VERSION ""

NS_ :

BS_:

BU_: Device Host

BO_ 3221225472 VECTOR__INDEPENDENT_SIG_MSG: 0 Vector__XXX
 SG_ IsolationDCDCShutdownReq : 0|1@1+ (1,0) [0|1] "" Vector__XXX
 SG_ DCDC_OutputVoltage : 0|9@1+ (0.1,0) [0|51.1] "V" Vector__XXX
 SG_ DCDC_OutputCurrent : 0|14@1- (0.1,0) [-819.2|819.1] "A" Vector__XXX
 SG_ DCDC_InputCurrent : 0|9@1- (0.1,0) [-25.6|25.5] "A" Vector__XXX
 SG_ DCDC_InputVoltage : 0|13@1+ (0.1,0) [0|819.1] "V" Vector__XXX

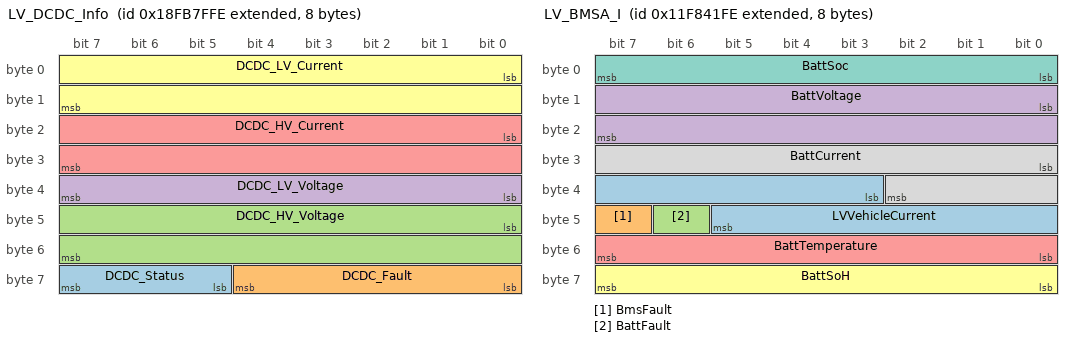
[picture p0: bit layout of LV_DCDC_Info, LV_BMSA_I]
BO_ 2566619134 LV_DCDC_Info: 8 Vector__XXX
 SG_ DCDC_Status : 61|3@1+ (1,0) [0|7] "" Vector__XXX
 SG_ DCDC_Fault : 56|5@1+ (1,0) [0|31] "" Vector__XXX
 SG_ DCDC_HV_Voltage : 40|16@1+ (0.1,0) [0|6553.5] "V" Vector__XXX
 SG_ DCDC_LV_Voltage : 32|8@1+ (0.2,0) [0|51] "V" Vector__XXX
 SG_ DCDC_HV_Current : 16|16@1+ (0.05,-1600) [-1600|1676.75] "A" Vector__XXX
 SG_ DCDC_LV_Current : 0|16@1+ (0.05,-1600) [-1600|1676.75] "A" Vector__XXX

BO_ 2448966142 LV_BMSA_I: 8 Vector__XXX
 SG_ LVVehicleCurrent : 35|11@1+ (0.25,-255) [-255|255] "A" Vector__XXX
 SG_ BmsFault : 47|1@1+ (1,0) [0|1] "" Vector__XXX
 SG_ BattFault : 46|1@1+ (1,0) [0|1] "" Vector__XXX
 SG_ BattVoltage : 8|16@1+ (0.001,0) [0|64.255] "V" Vector__XXX
 SG_ BattTemperature : 48|8@1+ (1,-40) [-40|210] "C" Vector__XXX
 SG_ BattSoH : 56|8@1+ (0.5,0) [0|125] "%" Vector__XXX
 SG_ BattSoc : 0|8@1+ (0.5,0) [0|125] "%" Vector__XXX
 SG_ BattCurrent : 24|11@1+ (0.25,-255) [-255|255] "A" Vector__XXX

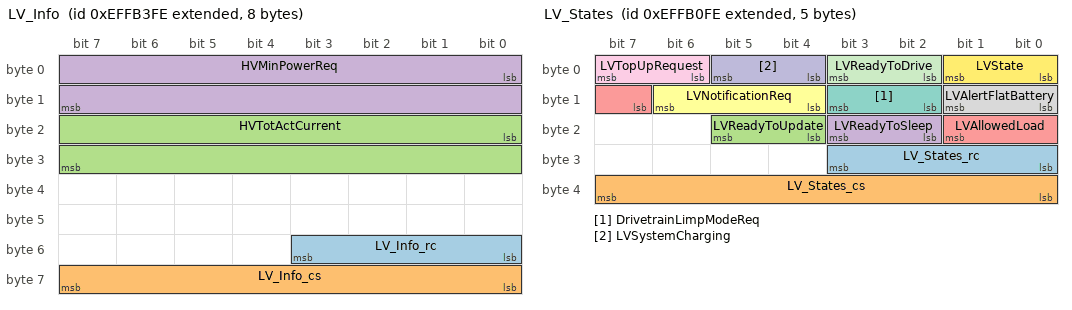
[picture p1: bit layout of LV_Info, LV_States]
BO_ 2399122430 LV_Info: 8 Vector__XXX
 SG_ LV_Info_rc : 48|4@1+ (1,0) [0|15] "" Vector__XXX
 SG_ LV_Info_cs : 56|8@1+ (1,0) [0|255] "" Vector__XXX
 SG_ HVTotActCurrent : 16|16@1+ (0.05,0) [0|3276.75] "A" Vector__XXX
 SG_ HVMinPowerReq : 0|16@1+ (0.1,0) [0|6553.5] "kW" Vector__XXX

BO_ 2399121662 LV_States: 5 Vector__XXX
 SG_ LV_States_rc : 24|4@1+ (1,0) [0|15] "" Vector__XXX
 SG_ LV_States_cs : 32|8@1+ (1,0) [0|255] "" Vector__XXX
 SG_ LVReadyToUpdate : 20|2@1+ (1,0) [0|3] "" Vector__XXX
 SG_ LVReadyToSleep : 18|2@1+ (1,0) [0|3] "" Vector__XXX
 SG_ LVAllowedLoad : 15|3@1+ (1,0) [0|7] "" Vector__XXX
 SG_ LVNotificationReq : 12|3@1+ (1,0) [0|7] "" Vector__XXX
 SG_ DrivetrainLimpModeReq : 10|2@1+ (1,0) [0|3] "" Vector__XXX
 SG_ LVAlertFlatBattery : 8|2@1+ (1,0) [0|3] "" Vector__XXX
 SG_ LVTopUpRequest : 6|2@1+ (1,0) [0|3] "" Vector__XXX
 SG_ LVSystemCharging : 4|2@1+ (1,0) [0|3] "" Vector__XXX
 SG_ LVReadyToDrive : 2|2@1+ (1,0) [0|3] "" Vector__XXX
 SG_ LVState : 0|2@1+ (1,0) [0|3] "" Vector__XXX

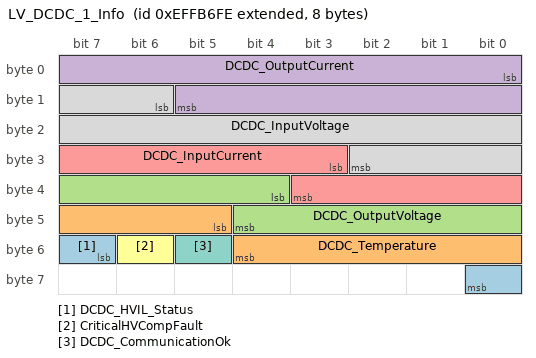
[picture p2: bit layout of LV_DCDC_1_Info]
BO_ 2399123198 LV_DCDC_1_Info: 8 Vector__XXX
 SG_ DCDC_HVIL_Status : 55|2@1+ (1,0) [0|0] "" Vector__XXX
 SG_ DCDC_Temperature : 45|8@1+ (1,-40) [-40|215] "Degree Celsius" Vector__XXX
 SG_ DCDC_OutputVoltage : 36|9@1+ (0.1,0) [0|51.1] "V" Vector__XXX
 SG_ DCDC_OutputCurrent : 0|14@1- (0.1,0) [-819.2|819.1] "A" Vector__XXX
 SG_ DCDC_InputCurrent : 27|9@1- (0.1,0) [-25.6|25.5] "A" Vector__XXX
 SG_ CriticalHVCompFault : 54|1@1+ (1,0) [0|1] "" Vector__XXX
 SG_ DCDC_CommunicationOk : 53|1@1+ (1,0) [0|1] "" Vector__XXX
 SG_ DCDC_InputVoltage : 14|13@1+ (0.1,0) [0|819.1] "V" Vector__XXX

CM_ "$File: //depot/auto/dbc/Software_Modules/LV_System/LVSYSOP/0.2.9.0/LVSYSOP.dbc $
$Change: 215979 $
$DateTime: 2024/08/21 10:08:09 $
$Revision: #1 $";
CM_ BO_ 3221225472 "This is a message for not used signals, created by Vector CANdb++ DBC OLE DB Provider.";
CM_ SG_ 3221225472 DCDC_OutputVoltage "DCDC output voltage";
CM_ SG_ 3221225472 DCDC_OutputCurrent "DCDC output current";
CM_ SG_ 3221225472 DCDC_InputCurrent "DCDC input current";
CM_ SG_ 3221225472 DCDC_InputVoltage "DCDC input voltage";
CM_ BO_ 2566619134 "Message with the 1st LV DCDC status information";
CM_ BO_ 2448966142 "Primary battery readings";
CM_ SG_ 2448966142 BmsFault "battery managment system fault state";
CM_ SG_ 2448966142 BattFault "battery fault state";
CM_ SG_ 2448966142 BattVoltage "battery voltage";
CM_ SG_ 2448966142 BattTemperature "battery temperature";
CM_ SG_ 2448966142 BattSoH "battery state of health";
CM_ SG_ 2448966142 BattSoc "battery state of charge";
CM_ SG_ 2448966142 BattCurrent "battery current";
CM_ BO_ 2399122430 "Message with LV info";
CM_ SG_ 2399122430 HVTotActCurrent "Total current of all DCDC";
CM_ SG_ 2399122430 HVMinPowerReq "Minimal Power for LV processing";
CM_ BO_ 2399121662 "Message with LV system states";
CM_ SG_ 2399121662 LVReadyToUpdate "Feedback that device ready for FW update";
CM_ SG_ 2399121662 LVReadyToSleep "Signals if the LV Controller is ready to sleep";
CM_ SG_ 2399121662 LVAllowedLoad "LV load permission depending on a load shedding request";
CM_ SG_ 2399121662 LVNotificationReq "LV Notification request";
CM_ SG_ 2399121662 DrivetrainLimpModeReq "Drivetrain Limp mode request";
CM_ SG_ 2399121662 LVAlertFlatBattery "flat battery alarm";
CM_ SG_ 2399121662 LVTopUpRequest "whether either of the LV Batteries require charging";
CM_ SG_ 2399121662 LVSystemCharging "ALDC LV Controller charging state";
CM_ SG_ 2399121662 LVReadyToDrive "ALDC LV Controller Ready to Drive state";
CM_ SG_ 2399121662 LVState "ALDC LV Controller state";
CM_ BO_ 2399123198 "Message with the 1st LV DCDC status information";
CM_ SG_ 2399123198 DCDC_HVIL_Status "DCDC High Voltage Interlock Loop Status";
CM_ SG_ 2399123198 DCDC_Temperature "DCDC temperature";
CM_ SG_ 2399123198 DCDC_OutputVoltage "DCDC output voltage";
CM_ SG_ 2399123198 DCDC_OutputCurrent "DCDC output current";
CM_ SG_ 2399123198 DCDC_InputCurrent "DCDC input current";
CM_ SG_ 2399123198 CriticalHVCompFault "Critical HV component fault";
CM_ SG_ 2399123198 DCDC_CommunicationOk "DCDC communication Ok flag";
CM_ SG_ 2399123198 DCDC_InputVoltage "DCDC input voltage";
BA_DEF_  "BusType" STRING ;
BA_DEF_  "DBName" STRING ;
BA_DEF_  "DatabaseVersion" STRING ;
BA_DEF_ BO_  "GenMsgCycleTime" INT 0 3600000;
BA_DEF_ BO_  "GenMsgDelayTime" INT 0 1000;
BA_DEF_ BO_  "GenMsgILSupport" ENUM  "No","Yes";
BA_DEF_ BO_  "GenMsgRequestable" INT 0 1;
BA_DEF_ BO_  "GenMsgSendType" ENUM  "cyclic","NotUsed","NotUsed","NotUsed","NotUsed","NotUsed","NotUsed","IfActive","noMsgSendType";
BA_DEF_ SG_  "GenSigEVName" STRING ;
BA_DEF_ SG_  "GenSigILSupport" ENUM  "No","Yes";
BA_DEF_ SG_  "GenSigSendType" ENUM  "Cyclic","OnWrite","OnWriteWithRepetition","OnChange","OnChangeWithRepetition","IfActive","IfActiveWithRepetition","NoSigSendType";
BA_DEF_ SG_  "GenSigStartValue" INT 0 2147483647;
BA_DEF_ BU_  "NmStationAddress" INT 0 255;
BA_DEF_  "ProtocolType" STRING ;
BA_DEF_  "SAE_J1939_21_SpecVersion" STRING ;
BA_DEF_  "SAE_J1939_71_SpecVersion" STRING ;
BA_DEF_  "SAE_J1939_73_SpecVersion" STRING ;
BA_DEF_  "SAE_J1939_75_SpecVersion" STRING ;
BA_DEF_  "SAE_J1939_81_SpecVersion" STRING ;
BA_DEF_  "SAE_J1939_DA_SpecVersion" STRING ;
BA_DEF_ BO_  "SendOnChange" ENUM  "No","Yes";
BA_DEF_ SG_  "SigType" ENUM  "Default","Range","RangeSigned","ASCII","Discrete","Control","ReferencePGN","DTC","StringDelimiter","StringLength","StringLengthControl","MessageCounter","MessageChecksum";
BA_DEF_ BO_  "VFrameFormat" ENUM  "StandardCAN","ExtendedCAN","reserved","J1939PG","reserved","reserved","reserved","reserved","reserved","reserved","reserved","reserved","reserved","reserved","StandardCAN_FD","ExtendedCAN_FD";
BA_DEF_ BO_  "Producer" STRING ;
BA_DEF_DEF_  "BusType" "";
BA_DEF_DEF_  "DBName" "";
BA_DEF_DEF_  "DatabaseVersion" "";
BA_DEF_DEF_  "GenMsgCycleTime" 0;
BA_DEF_DEF_  "GenMsgDelayTime" 0;
BA_DEF_DEF_  "GenMsgILSupport" "Yes";
BA_DEF_DEF_  "GenMsgRequestable" 1;
BA_DEF_DEF_  "GenMsgSendType" "noMsgSendType";
BA_DEF_DEF_  "GenSigEVName" "Env@Nodename_@Signame";
BA_DEF_DEF_  "GenSigILSupport" "Yes";
BA_DEF_DEF_  "GenSigSendType" "NoSigSendType";
BA_DEF_DEF_  "GenSigStartValue" 0;
BA_DEF_DEF_  "NmStationAddress" 254;
BA_DEF_DEF_  "ProtocolType" "";
BA_DEF_DEF_  "SAE_J1939_21_SpecVersion" "";
BA_DEF_DEF_  "SAE_J1939_71_SpecVersion" "";
BA_DEF_DEF_  "SAE_J1939_73_SpecVersion" "";
BA_DEF_DEF_  "SAE_J1939_75_SpecVersion" "";
BA_DEF_DEF_  "SAE_J1939_81_SpecVersion" "";
BA_DEF_DEF_  "SAE_J1939_DA_SpecVersion" "";
BA_DEF_DEF_  "SendOnChange" "No";
BA_DEF_DEF_  "SigType" "Default";
BA_DEF_DEF_  "VFrameFormat" "J1939PG";
BA_DEF_DEF_  "Producer" "";
BA_ "BusType" "CAN";
BA_ "DatabaseVersion" "1.0";
BA_ "ProtocolType" "J1939";
BA_ "SAE_J1939_21_SpecVersion" "2006-10";
BA_ "SAE_J1939_71_SpecVersion" "2012-10";
BA_ "SAE_J1939_73_SpecVersion" "2012-10";
BA_ "SAE_J1939_75_SpecVersion" "2012-05";
BA_ "SAE_J1939_81_SpecVersion" "2012-05";
BA_ "SAE_J1939_DA_SpecVersion" "2015-01";
BA_ "DBName" "LV";
BA_ "Producer" BO_ 2566619134 "LVPS";
BA_ "GenMsgCycleTime" BO_ 2566619134 10000;
BA_ "GenMsgSendType" BO_ 2566619134 0;
BA_ "Producer" BO_ 2448966142 "LVPS";
BA_ "GenMsgCycleTime" BO_ 2448966142 1000;
BA_ "GenMsgSendType" BO_ 2448966142 0;
BA_ "Producer" BO_ 2399122430 "LVPS";
BA_ "GenMsgCycleTime" BO_ 2399122430 100;
BA_ "GenMsgSendType" BO_ 2399122430 0;
BA_ "Producer" BO_ 2399121662 "LVPS";
BA_ "SendOnChange" BO_ 2399121662 1;
BA_ "GenMsgDelayTime" BO_ 2399121662 100;
BA_ "GenMsgCycleTime" BO_ 2399121662 1000;
BA_ "Producer" BO_ 2399123198 "LVPS";
BA_ "GenMsgSendType" BO_ 2399123198 0;
BA_ "GenMsgCycleTime" BO_ 2399123198 100;
BA_ "GenSigStartValue" SG_ 2566619134 DCDC_HV_Current 32000;
BA_ "GenSigStartValue" SG_ 2566619134 DCDC_LV_Current 32000;
BA_ "GenSigStartValue" SG_ 2448966142 LVVehicleCurrent 1024;
BA_ "SigType" SG_ 2448966142 BattVoltage 1;
BA_ "SigType" SG_ 2448966142 BattTemperature 1;
BA_ "GenSigStartValue" SG_ 2448966142 BattTemperature 40;
BA_ "SigType" SG_ 2448966142 BattSoH 1;
BA_ "SigType" SG_ 2448966142 BattSoc 1;
BA_ "SigType" SG_ 2448966142 BattCurrent 1;
BA_ "GenSigStartValue" SG_ 2448966142 BattCurrent 1020;
BA_ "SigType" SG_ 2399122430 LV_Info_rc 11;
BA_ "SigType" SG_ 2399122430 LV_Info_cs 12;
BA_ "SigType" SG_ 2399122430 HVTotActCurrent 1;
BA_ "SigType" SG_ 2399121662 LV_States_rc 11;
BA_ "SigType" SG_ 2399121662 LV_States_cs 12;
BA_ "GenSigStartValue" SG_ 2399121662 LVAllowedLoad 2;
BA_ "GenSigStartValue" SG_ 2399121662 LVReadyToDrive 3;
BA_ "GenSigStartValue" SG_ 2399123198 DCDC_HVIL_Status 3;
BA_ "GenSigStartValue" SG_ 2399123198 DCDC_Temperature 40;
VAL_ 2566619134 DCDC_Status 7 "Invalid" 6 "Reserved" 5 "Degradation" 4 "Error" 3 "Conversion" 2 "Standby" 1 "Init" 0 "Off" ;
VAL_ 2566619134 DCDC_Fault 19 "InpVoltage_Overvoltage" 18 "Shortcircuit_Protection" 17 "Output_Overcurrent" 16 "Output_Overvoltage" 15 "Cavity_Overcurrent" 14 "Temp_Sensor_Fault" 13 "CoolantTemp_tooHigh" 12 "CoolantTemp_tooLow" 11 "BatVolt12V_tooLow" 10 "BatVolt12V_tooHigh" 9 "InpVoltage_Undervoltage" 8 "ROM_Timeout" 7 "RAM_Timeout" 6 "Send_Message_Timeout" 5 "VCU_Node_Loss" 4 "BMS_Node_Loss" 3 "CGW_Node_Loss" 2 "Bus_Off" 1 "Abnormal_WakeUp" 0 "No_Fault" ;
VAL_ 2399121662 LVReadyToUpdate 3 "NA" 2 "Error" 1 "Ready" 0 "NotReady" ;
VAL_ 2399121662 LVReadyToSleep 3 "Not available" 2 "Fault" 1 "Ready" 0 "Not Ready" ;
VAL_ 2399121662 LVAllowedLoad 4 "NotAllowed" 3 "AllActive" 7 "NotAvailable" 6 "Error" 2 "CriticalOnly" 1 "PrimaryAllowed" 0 "AllAllowed" ;
VAL_ 2399121662 LVNotificationReq 6 "Not Available" 5 "Fault" 4 "Stop_safely" 3 "Drive_with_caution" 2 "LV_power_supply_limited" 1 "LV_system_requires_service" 0 "No_notification_required" ;
VAL_ 2399121662 DrivetrainLimpModeReq 3 "NA" 2 "Error" 1 "Requested" 0 "Not requested" ;
VAL_ 2399121662 LVAlertFlatBattery 3 "NA" 2 "Error" 1 "Alert" 0 "Normal" ;
VAL_ 2399121662 LVTopUpRequest 3 "NA" 2 "Error" 1 "Required" 0 "Not required" ;
VAL_ 2399121662 LVSystemCharging 3 "NA" 2 "Error" 1 "Charging" 0 "Not charging " ;
VAL_ 2399121662 LVReadyToDrive 3 "NA" 2 "Error" 1 "Ready" 0 "Not Ready" ;
VAL_ 2399121662 LVState 3 "NA" 2 "Fault" 0 "OFF" 1 "ON" ;
VAL_ 2399123198 DCDC_HVIL_Status 0 "Init" 1 "Ok" 2 "Fault" 3 "NA" ;
